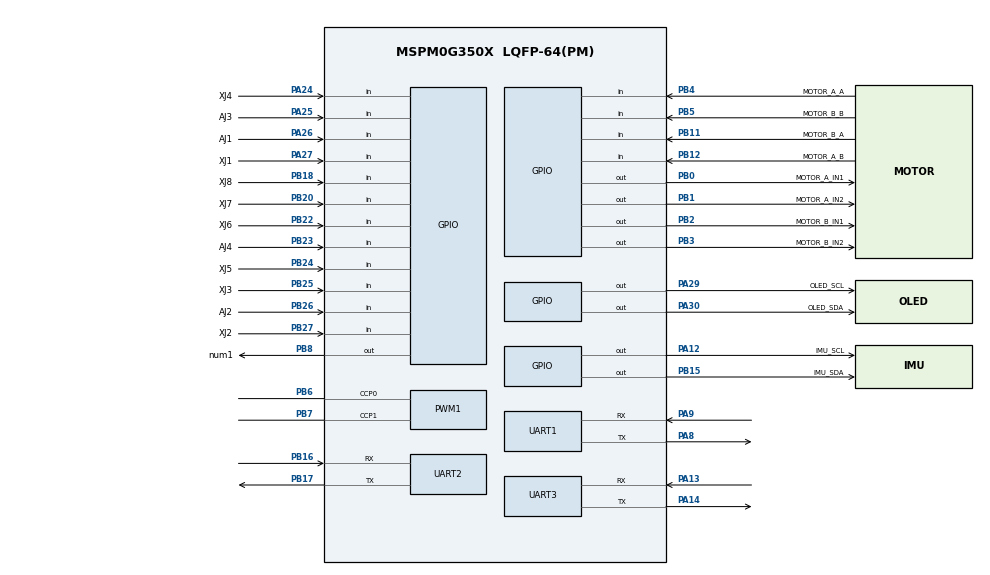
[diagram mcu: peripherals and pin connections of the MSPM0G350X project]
/**
 * @cliArgs --device "MSPM0G350X" --part "Default" --package "LQFP-64(PM)" --product "mspm0_sdk@2.10.00.04"
 * @versions {"tool":"1.26.2+4477"}
 */

/**
 * Import the modules used in this configuration.
 */
const GPIO   = scripting.addModule("/ti/driverlib/GPIO", {}, false);
const GPIO1  = GPIO.addInstance();
const GPIO2  = GPIO.addInstance();
const GPIO3  = GPIO.addInstance();
const GPIO4  = GPIO.addInstance();
const GPIO5  = GPIO.addInstance();
const GPIO6  = GPIO.addInstance();
const GPIO7  = GPIO.addInstance();
const PWM    = scripting.addModule("/ti/driverlib/PWM", {}, false);
const PWM1   = PWM.addInstance();
const SYSCTL = scripting.addModule("/ti/driverlib/SYSCTL");
const TIMER  = scripting.addModule("/ti/driverlib/TIMER", {}, false);
const TIMER1 = TIMER.addInstance();
const UART   = scripting.addModule("/ti/driverlib/UART", {}, false);
const UART1  = UART.addInstance();
const UART2  = UART.addInstance();
const UART3  = UART.addInstance();

/**
 * Write custom configuration values to the imported modules.
 */
const divider9       = system.clockTree["UDIV"];
divider9.divideValue = 2;

const multiplier2         = system.clockTree["PLL_QDIV"];
multiplier2.multiplyValue = 4;

const mux4       = system.clockTree["EXHFMUX"];
mux4.inputSelect = "EXHFMUX_XTAL";

const mux8       = system.clockTree["HSCLKMUX"];
mux8.inputSelect = "HSCLKMUX_SYSPLL0";

const mux12       = system.clockTree["SYSPLLMUX"];
mux12.inputSelect = "zSYSPLLMUX_HFCLK";

const pinFunction4       = system.clockTree["HFXT"];
pinFunction4.inputFreq   = 40;
pinFunction4.enable      = true;
pinFunction4.HFXTStartup = 128;

GPIO1.$name                         = "OLED";
GPIO1.associatedPins.create(2);
GPIO1.associatedPins[0].$name       = "OLED_SCL";
GPIO1.associatedPins[0].pin.$assign = "PA29";
GPIO1.associatedPins[1].$name       = "OLED_SDA";
GPIO1.associatedPins[1].pin.$assign = "PA30";

const Board = scripting.addModule("/ti/driverlib/Board", {}, false);

GPIO2.$name                         = "MOTOR_DIR";
GPIO2.associatedPins.create(4);
GPIO2.associatedPins[0].$name       = "MOTOR_A_IN1";
GPIO2.associatedPins[0].pin.$assign = "PB0";
GPIO2.associatedPins[1].$name       = "MOTOR_A_IN2";
GPIO2.associatedPins[1].pin.$assign = "PB1";
GPIO2.associatedPins[2].$name       = "MOTOR_B_IN1";
GPIO2.associatedPins[2].pin.$assign = "PB2";
GPIO2.associatedPins[3].$name       = "MOTOR_B_IN2";
GPIO2.associatedPins[3].pin.$assign = "PB3";

GPIO3.$name                              = "ENCODER";
GPIO3.associatedPins.create(4);
GPIO3.associatedPins[0].$name            = "MOTOR_A_A";
GPIO3.associatedPins[0].direction        = "INPUT";
GPIO3.associatedPins[0].interruptEn      = true;
GPIO3.associatedPins[0].internalResistor = "PULL_UP";
GPIO3.associatedPins[0].polarity         = "RISE_FALL";
GPIO3.associatedPins[0].pin.$assign      = "PB4";
GPIO3.associatedPins[1].$name            = "MOTOR_A_B";
GPIO3.associatedPins[1].direction        = "INPUT";
GPIO3.associatedPins[1].internalResistor = "PULL_UP";
GPIO3.associatedPins[1].polarity         = "RISE_FALL";
GPIO3.associatedPins[1].pin.$assign      = "PB12";
GPIO3.associatedPins[2].$name            = "MOTOR_B_A";
GPIO3.associatedPins[2].direction        = "INPUT";
GPIO3.associatedPins[2].interruptEn      = true;
GPIO3.associatedPins[2].internalResistor = "PULL_UP";
GPIO3.associatedPins[2].polarity         = "RISE_FALL";
GPIO3.associatedPins[2].pin.$assign      = "PB11";
GPIO3.associatedPins[3].$name            = "MOTOR_B_B";
GPIO3.associatedPins[3].direction        = "INPUT";
GPIO3.associatedPins[3].internalResistor = "PULL_UP";
GPIO3.associatedPins[3].interruptEn      = true;
GPIO3.associatedPins[3].polarity         = "RISE_FALL";
GPIO3.associatedPins[3].pin.$assign      = "PB5";

GPIO4.$name                         = "XUNJI";
GPIO4.associatedPins.create(8);
GPIO4.associatedPins[0].direction   = "INPUT";
GPIO4.associatedPins[0].$name       = "XJ1";
GPIO4.associatedPins[0].pin.$assign = "PA27";
GPIO4.associatedPins[1].$name       = "XJ2";
GPIO4.associatedPins[1].direction   = "INPUT";
GPIO4.associatedPins[1].pin.$assign = "PB27";
GPIO4.associatedPins[2].$name       = "XJ3";
GPIO4.associatedPins[2].direction   = "INPUT";
GPIO4.associatedPins[2].pin.$assign = "PB25";
GPIO4.associatedPins[3].$name       = "XJ4";
GPIO4.associatedPins[3].direction   = "INPUT";
GPIO4.associatedPins[3].pin.$assign = "PA24";
GPIO4.associatedPins[4].$name       = "XJ5";
GPIO4.associatedPins[4].direction   = "INPUT";
GPIO4.associatedPins[4].pin.$assign = "PB24";
GPIO4.associatedPins[5].$name       = "XJ6";
GPIO4.associatedPins[5].direction   = "INPUT";
GPIO4.associatedPins[5].pin.$assign = "PB22";
GPIO4.associatedPins[6].$name       = "XJ7";
GPIO4.associatedPins[6].direction   = "INPUT";
GPIO4.associatedPins[6].pin.$assign = "PB20";
GPIO4.associatedPins[7].$name       = "XJ8";
GPIO4.associatedPins[7].direction   = "INPUT";
GPIO4.associatedPins[7].pin.$assign = "PB18";

GPIO5.$name                         = "Buzzer";
GPIO5.associatedPins[0].$name       = "num1";
GPIO5.associatedPins[0].pin.$assign = "PB8";

GPIO6.$name                               = "AJ";
GPIO6.associatedPins.create(4);
GPIO6.associatedPins[0].$name             = "AJ1";
GPIO6.associatedPins[0].direction         = "INPUT";
GPIO6.associatedPins[0].internalResistor  = "PULL_UP";
GPIO6.associatedPins[0].interruptEn       = true;
GPIO6.associatedPins[0].polarity          = "FALL";
GPIO6.associatedPins[0].interruptPriority = "0";
GPIO6.associatedPins[0].pin.$assign       = "PA26";
GPIO6.associatedPins[1].$name             = "AJ2";
GPIO6.associatedPins[1].direction         = "INPUT";
GPIO6.associatedPins[1].internalResistor  = "PULL_UP";
GPIO6.associatedPins[1].interruptEn       = true;
GPIO6.associatedPins[1].polarity          = "FALL";
GPIO6.associatedPins[1].interruptPriority = "0";
GPIO6.associatedPins[1].pin.$assign       = "PB26";
GPIO6.associatedPins[2].$name             = "AJ3";
GPIO6.associatedPins[2].direction         = "INPUT";
GPIO6.associatedPins[2].internalResistor  = "PULL_UP";
GPIO6.associatedPins[2].interruptEn       = true;
GPIO6.associatedPins[2].interruptPriority = "0";
GPIO6.associatedPins[2].polarity          = "FALL";
GPIO6.associatedPins[2].pin.$assign       = "PA25";
GPIO6.associatedPins[3].$name             = "AJ4";
GPIO6.associatedPins[3].direction         = "INPUT";
GPIO6.associatedPins[3].internalResistor  = "PULL_UP";
GPIO6.associatedPins[3].interruptEn       = true;
GPIO6.associatedPins[3].interruptPriority = "0";
GPIO6.associatedPins[3].polarity          = "FALL";
GPIO6.associatedPins[3].pin.$assign       = "PB23";

GPIO7.$name                         = "IMU_IIC";
GPIO7.associatedPins.create(2);
GPIO7.associatedPins[0].$name       = "IMU_SCL";
GPIO7.associatedPins[0].pin.$assign = "PA12";
GPIO7.associatedPins[1].$name       = "IMU_SDA";
GPIO7.associatedPins[1].pin.$assign = "PB15";

PWM1.timerCount                         = 4000;
PWM1.$name                              = "PWM_TB6612";
PWM1.pwmMode                            = "EDGE_ALIGN_UP";
PWM1.peripheral.ccp0Pin.$assign         = "PB6";
PWM1.peripheral.ccp1Pin.$assign         = "PB7";
PWM1.PWM_CHANNEL_0.$name                = "ti_driverlib_pwm_PWMTimerCC0";
PWM1.PWM_CHANNEL_1.$name                = "ti_driverlib_pwm_PWMTimerCC1";
PWM1.ccp0PinConfig.$name                = "ti_driverlib_gpio_GPIOPinGeneric0";
PWM1.ccp0PinConfig.direction            = scripting.forceWrite("OUTPUT");
PWM1.ccp0PinConfig.hideOutputInversion  = scripting.forceWrite(false);
PWM1.ccp0PinConfig.onlyInternalResistor = scripting.forceWrite(false);
PWM1.ccp0PinConfig.passedPeripheralType = scripting.forceWrite("Digital");
PWM1.ccp1PinConfig.$name                = "ti_driverlib_gpio_GPIOPinGeneric1";
PWM1.ccp1PinConfig.direction            = scripting.forceWrite("OUTPUT");
PWM1.ccp1PinConfig.hideOutputInversion  = scripting.forceWrite(false);
PWM1.ccp1PinConfig.onlyInternalResistor = scripting.forceWrite(false);
PWM1.ccp1PinConfig.passedPeripheralType = scripting.forceWrite("Digital");

SYSCTL.forceDefaultClkConfig = true;
SYSCTL.clockTreeEn           = true;

TIMER1.timerMode          = "PERIODIC_UP";
TIMER1.timerPeriod        = "1ms";
TIMER1.timerClkPrescale   = 80;
TIMER1.$name              = "TIMER_TICK";
TIMER1.interruptPriority  = "0";
TIMER1.interrupts         = ["LOAD"];
TIMER1.peripheral.$assign = "TIMG0";

UART1.$name                            = "UART_JY901";
UART1.peripheral.rxPin.$assign         = "PA9";
UART1.peripheral.txPin.$assign         = "PA8";
UART1.txPinConfig.$name                = "ti_driverlib_gpio_GPIOPinGeneric2";
UART1.txPinConfig.direction            = scripting.forceWrite("OUTPUT");
UART1.txPinConfig.hideOutputInversion  = scripting.forceWrite(false);
UART1.txPinConfig.onlyInternalResistor = scripting.forceWrite(false);
UART1.txPinConfig.passedPeripheralType = scripting.forceWrite("Digital");
UART1.rxPinConfig.$name                = "ti_driverlib_gpio_GPIOPinGeneric3";
UART1.rxPinConfig.hideOutputInversion  = scripting.forceWrite(false);
UART1.rxPinConfig.onlyInternalResistor = scripting.forceWrite(false);
UART1.rxPinConfig.passedPeripheralType = scripting.forceWrite("Digital");

UART2.$name                            = "UART_BT";
UART2.enabledInterrupts                = ["RX"];
UART2.peripheral.rxPin.$assign         = "PB16";
UART2.peripheral.txPin.$assign         = "PB17";
UART2.txPinConfig.$name                = "ti_driverlib_gpio_GPIOPinGeneric4";
UART2.txPinConfig.direction            = scripting.forceWrite("OUTPUT");
UART2.txPinConfig.hideOutputInversion  = scripting.forceWrite(false);
UART2.txPinConfig.onlyInternalResistor = scripting.forceWrite(false);
UART2.txPinConfig.passedPeripheralType = scripting.forceWrite("Digital");
UART2.rxPinConfig.$name                = "ti_driverlib_gpio_GPIOPinGeneric5";
UART2.rxPinConfig.hideOutputInversion  = scripting.forceWrite(false);
UART2.rxPinConfig.onlyInternalResistor = scripting.forceWrite(false);
UART2.rxPinConfig.passedPeripheralType = scripting.forceWrite("Digital");

UART3.$name                            = "UART_DEBUG";
UART3.peripheral.rxPin.$assign         = "PA13";
UART3.peripheral.txPin.$assign         = "PA14";
UART3.txPinConfig.$name                = "ti_driverlib_gpio_GPIOPinGeneric6";
UART3.txPinConfig.direction            = scripting.forceWrite("OUTPUT");
UART3.txPinConfig.hideOutputInversion  = scripting.forceWrite(false);
UART3.txPinConfig.onlyInternalResistor = scripting.forceWrite(false);
UART3.txPinConfig.passedPeripheralType = scripting.forceWrite("Digital");
UART3.rxPinConfig.$name                = "ti_driverlib_gpio_GPIOPinGeneric7";
UART3.rxPinConfig.hideOutputInversion  = scripting.forceWrite(false);
UART3.rxPinConfig.onlyInternalResistor = scripting.forceWrite(false);
UART3.rxPinConfig.passedPeripheralType = scripting.forceWrite("Digital");

/**
 * Pinmux solution for unlocked pins/peripherals. This ensures that minor changes to the automatic solver in a future
 * version of the tool will not impact the pinmux you originally saw.  These lines can be completely deleted in order to
 * re-solve from scratch.
 */
pinFunction4.peripheral.$suggestSolution           = "SYSCTL";
pinFunction4.peripheral.hfxInPin.$suggestSolution  = "PA5";
pinFunction4.peripheral.hfxOutPin.$suggestSolution = "PA6";
Board.peripheral.$suggestSolution                  = "DEBUGSS";
Board.peripheral.swclkPin.$suggestSolution         = "PA20";
Board.peripheral.swdioPin.$suggestSolution         = "PA19";
PWM1.peripheral.$suggestSolution                   = "TIMG6";
UART1.peripheral.$suggestSolution                  = "UART1";
UART2.peripheral.$suggestSolution                  = "UART2";
UART3.peripheral.$suggestSolution                  = "UART3";
